# nrf9120 register map
Vendor: Nordic Semiconductor; Series: nrf91; File version: 1
CPU: CM33 r0p4, little endian, MPU, FPU, 3 interrupt priority bits, 69 interrupts
Registers are 32-bit, read-write, reset 0x0 unless marked. A register's access mark holds for its fields unless they carry their own. Offsets are from the block's base; [hi:lo] are bit positions; lines under a group give offsets from that group; {n}, {i} and the like mark numbered series; 'fields as' and 'values as' point back to an identical list.

## CTRL_AP_PERI_S — Control access port
Base 0x50006000
0x400 MAILBOX group — Unspecified
  0x00 RXDATA ro — Data sent from the debugger to the CPU.
    [31:0] RXDATA — Data received from debugger
  0x04 RXSTATUS ro — This register shows a status that indicates if data sent from the debugger to the CPU has been read.
    [0] RXSTATUS — Status of data in register RXDATA
      0=No data pending in register RXDATA; 1=Data pending in register RXDATA
  0x80 TXDATA — Data sent from the CPU to the debugger.
    [31:0] TXDATA — Data sent to debugger
  0x84 TXSTATUS ro — This register shows a status that indicates if the data sent from the CPU to the debugger has been read.
    [0] TXSTATUS — Status of data in register TXDATA
      0=No data pending in register TXDATA; 1=Data pending in register TXDATA
0x500 ERASEPROTECT group — Unspecified
  0x00 LOCK rw-once — This register locks the ERASEPROTECT.DISABLE register from being written until next reset.
    [0] LOCK — Lock ERASEPROTECT.DISABLE register from being written until next reset
      0=Unlocked (Register ERASEPROTECT.DISABLE is writeable); 1=Locked (Register ERASEPROTECT.DISABLE is read-only)
  0x04 DISABLE rw-once — This register disables the ERASEPROTECT register and performs an ERASEALL operation.
    [31:0] KEY — The ERASEALL sequence is initiated if the value of the KEY fields are non-zero and the KEY fields match on both the CPU and debugger sides.

## DPPIC_NS — Distributed programmable peripheral interconnect controller 0
Base 0x40017000
Same registers: DPPIC_S 0x50017000
{0x0+8i} TASKS_CHG[{i}] (i=0..5) group — Channel group tasks
  0x00 EN wo — Description cluster: Enable channel group n
    [0] EN — Enable channel group n
      1=Trigger task
  0x04 DIS wo — Description cluster: Disable channel group n
    [0] DIS — Disable channel group n
      1=Trigger task
{0x80+8i} SUBSCRIBE_CHG[{i}] (i=0..5) group — Subscribe configuration for tasks
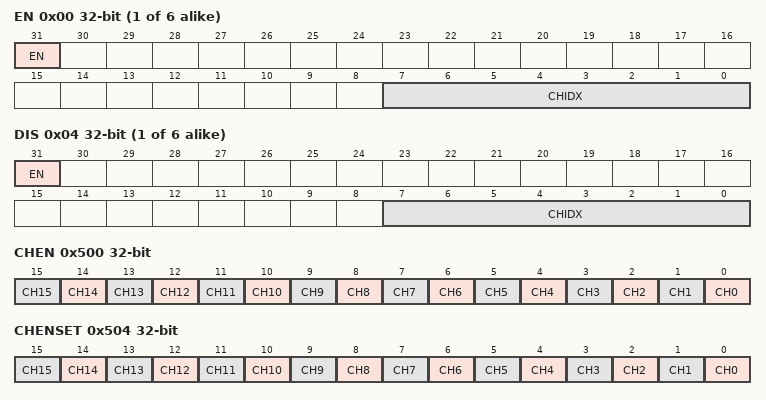
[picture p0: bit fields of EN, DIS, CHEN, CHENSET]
  0x00 EN — Description cluster: Subscribe configuration for task CHG[n].EN
    [31] EN
      0=Disabled (Disable subscription); 1=Enabled (Enable subscription)
    [7:0] CHIDX — DPPI channel that task CHG[n].EN will subscribe to
  0x04 DIS — Description cluster: Subscribe configuration for task CHG[n].DIS
    [31] EN
      values as SUBSCRIBE_CHG[0].EN.EN
    [7:0] CHIDX — DPPI channel that task CHG[n].DIS will subscribe to
0x500 CHEN — Channel enable register
  [all] fields
    0=Disabled (Disable channel); 1=Enabled (Enable channel)
  [n] CH{n} (n=0..15) — Enable or disable channel {n}
0x504 CHENSET write-1-sets — Channel enable set register
  [all] fields
    on read: 0=Disabled (Read: Channel disabled); 1=Enabled (Read: Channel enabled) | on write: 1=Set (Write: Enable channel)
  [n] CH{n} (n=0..15) — Channel {n} enable set register. Writing 0 has no effect.
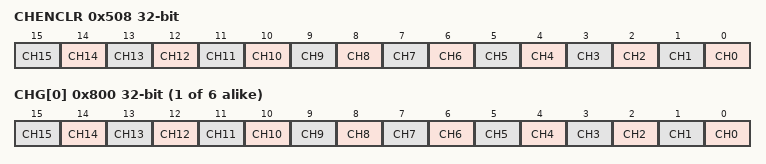
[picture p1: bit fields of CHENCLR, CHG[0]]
0x508 CHENCLR write-1-clears — Channel enable clear register
  [all] fields
    on read: 0=Disabled (Read: Channel disabled); 1=Enabled (Read: Channel enabled) | on write: 1=Clear (Write: Disable channel)
  [n] CH{n} (n=0..15) — Channel {n} enable clear register. Writing 0 has no effect.
{0x800+4i} CHG[{i}] (i=0..5) — Description collection: Channel group n Note: Writes to this register are ignored if either SUBSCRIBE_CHG[n].EN or SUBSCRIBE_CHG[n].DIS is enabled
  [all] fields
    0=Excluded; 1=Included
  [n] CH{n} (n=0..15) — Include or exclude channel {n}

## WDT_NS — Watchdog Timer 0
Base 0x40018000
Same registers: WDT_S 0x50018000
0x00 TASKS_START wo — Start the watchdog
  [0] TASKS_START
    1=Trigger task
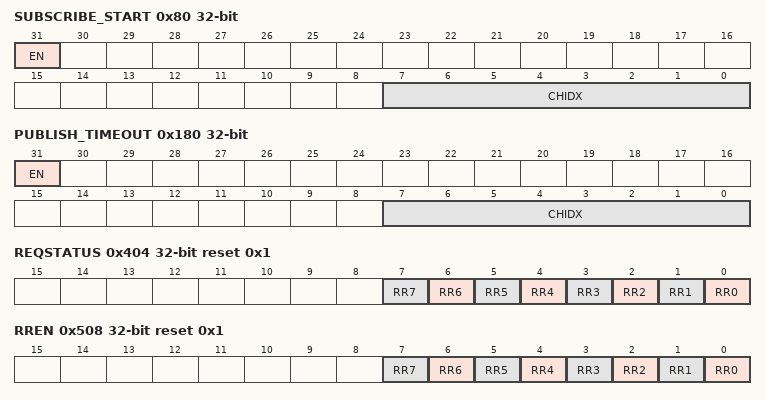
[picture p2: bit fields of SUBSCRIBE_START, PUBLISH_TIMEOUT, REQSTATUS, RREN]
0x80 SUBSCRIBE_START — Subscribe configuration for task START
  [31] EN
    0=Disabled (Disable subscription); 1=Enabled (Enable subscription)
  [7:0] CHIDX — DPPI channel that task START will subscribe to
0x100 EVENTS_TIMEOUT — Watchdog timeout
  [0] EVENTS_TIMEOUT
    0=NotGenerated (Event not generated); 1=Generated (Event generated)
0x180 PUBLISH_TIMEOUT — Publish configuration for event TIMEOUT
  [31] EN
    0=Disabled (Disable publishing); 1=Enabled (Enable publishing)
  [7:0] CHIDX — DPPI channel that event TIMEOUT will publish to
0x304 INTENSET — Enable interrupt
  [0] TIMEOUT — Write '1' to enable interrupt for event TIMEOUT
    on read: 0=Disabled (Read: Disabled); 1=Enabled (Read: Enabled) | on write: 1=Set (Enable)
0x308 INTENCLR — Disable interrupt
  [0] TIMEOUT — Write '1' to disable interrupt for event TIMEOUT
    on read: 0=Disabled (Read: Disabled); 1=Enabled (Read: Enabled) | on write: 1=Clear (Disable)
0x400 RUNSTATUS ro
  [0] RUNSTATUSWDT — Indicates whether or not the watchdog is running
    0=NotRunning (Watchdog not running); 1=Running (Watchdog is running)
0x404 REQSTATUS ro reset 0x1 — Request status
  [n] RR{n} (n=0..7) — Request status for RR[{n}] register
    0=DisabledOrRequested (RR[{n}] register is not enabled, or are already requesting reload); 1=EnabledAndUnrequested (RR[{n}] register is enabled, and are not yet requesting reload)
0x504 CRV reset 0xFFFFFFFF — Counter reload value
  [31:0] CRV — Counter reload value in number of cycles of the 32.768 kHz clock
0x508 RREN reset 0x1 — Enable register for reload request registers
  [n] RR{n} (n=0..7) — Enable or disable RR[{n}] register
    0=Disabled (Disable RR[{n}] register); 1=Enabled (Enable RR[{n}] register)
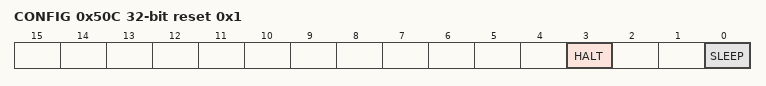
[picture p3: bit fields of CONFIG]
0x50C CONFIG reset 0x1 — Configuration register
  [3] HALT — Configure the watchdog to either be paused, or kept running, while the CPU is halted by the debugger
    0=Pause watchdog while the CPU is halted by the debugger; 1=Run (Keep the watchdog running while the CPU is halted by the debugger)
  [0] SLEEP — Configure the watchdog to either be paused, or kept running, while the CPU is sleeping
    0=Pause watchdog while the CPU is sleeping; 1=Run (Keep the watchdog running while the CPU is sleeping)
{0x600+4i} RR[{i}] (i=0..7) wo — Description collection: Reload request n
  [31:0] RR — Reload request register
    0x6E524635=Reload (Value to request a reload of the watchdog timer)
